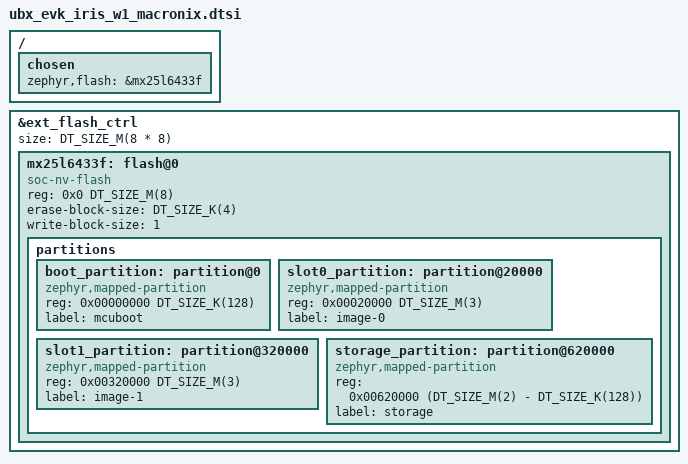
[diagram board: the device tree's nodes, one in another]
/*
 * Copyright (c) 2025 u-blox AG
 *
 * SPDX-License-Identifier: Apache-2.0
 */

/ {
	chosen {
		zephyr,flash = &mx25l6433f;
	};
};

&ext_flash_ctrl {
	ranges = <0x0 0x18000000 DT_SIZE_M(8)>;
	/* Macronix MX25L6433F - 8MB / 64Mbit */
	size = <DT_SIZE_M(8 * 8)>;

	mx25l6433f: flash@0 {
		compatible = "soc-nv-flash";
		reg = <0x0 DT_SIZE_M(8)>;
		ranges;
		erase-block-size = <DT_SIZE_K(4)>;
		write-block-size = <1>;

		#address-cells = <1>;
		#size-cells = <1>;

		partitions {
			ranges;
			#address-cells = <1>;
			#size-cells = <1>;

			boot_partition: partition@0 {
				compatible = "zephyr,mapped-partition";
				reg = <0x00000000 DT_SIZE_K(128)>;
				label = "mcuboot";
			};

			slot0_partition: partition@20000 {
				compatible = "zephyr,mapped-partition";
				reg = <0x00020000 DT_SIZE_M(3)>;
				label = "image-0";
			};

			slot1_partition: partition@320000 {
				compatible = "zephyr,mapped-partition";
				reg = <0x00320000 DT_SIZE_M(3)>;
				label = "image-1";
			};

			storage_partition: partition@620000 {
				compatible = "zephyr,mapped-partition";
				reg = <0x00620000 (DT_SIZE_M(2) - DT_SIZE_K(128))>;
				label = "storage";
			};
		};
	};
};
